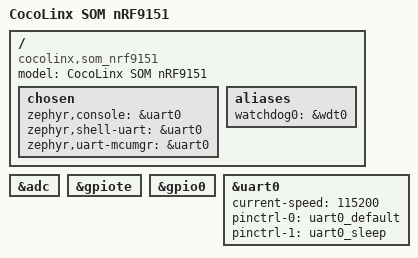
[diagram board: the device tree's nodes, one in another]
/*
 * Copyright (c) 2025 cocolinx
 *
 * SPDX-License-Identifier: Apache-2.0
 */
#include "cocolinx_som_nrf9151_common-pinctrl.dtsi"
#include <zephyr/dt-bindings/input/input-event-codes.h>

/ {
	model = "CocoLinx SOM nRF9151";
	compatible = "cocolinx,som_nrf9151";

	chosen {
		zephyr,console = &uart0;
		zephyr,shell-uart = &uart0;
		zephyr,uart-mcumgr = &uart0;
	};

	aliases {
		watchdog0 = &wdt0;
	};
};

&adc {
	status = "okay";
};

&gpiote {
	status = "okay";
};

&gpio0 {
	status = "okay";
};

&uart0 {
	status = "okay";
	current-speed = <115200>;
	pinctrl-0 = <&uart0_default>;
	pinctrl-1 = <&uart0_sleep>;
	pinctrl-names = "default", "sleep";
};

/* Include default memory partition configuration file */
#include <nordic/nrf91xx_partition.dtsi>
